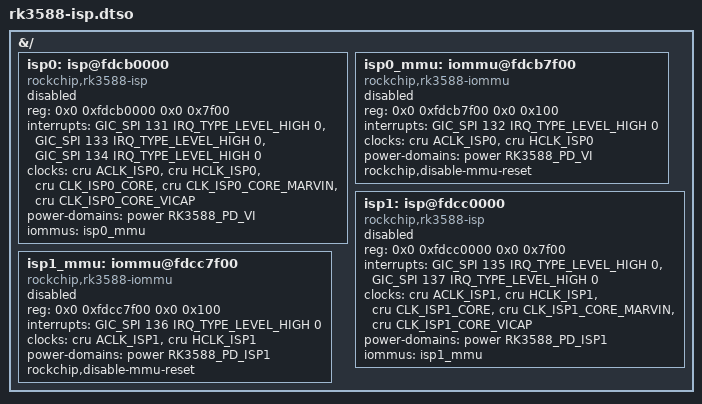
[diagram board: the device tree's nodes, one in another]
// SPDX-License-Identifier: (GPL-2.0+ OR MIT)
/*
 * RK3588 ISP nodes, generated by scripts/extract-oot-from-patches.sh from the
 * rk3588-base.dtsi hunk of patches/kernel/mainline/0002. Do not edit.
 *
 * Adds isp0/isp1 and their IOMMUs (disabled) for stock kernels whose DTBs
 * lack them. apply-overlays.sh applies this before any camera overlay.
 */

/dts-v1/;
/plugin/;

#include <dt-bindings/clock/rockchip,rk3588-cru.h>
#include <dt-bindings/interrupt-controller/arm-gic.h>
#include <dt-bindings/power/rk3588-power.h>

&{/} {
	isp0: isp@fdcb0000 {
		compatible = "rockchip,rk3588-isp";
		reg = <0x0 0xfdcb0000 0x0 0x7f00>;
		interrupts = <GIC_SPI 131 IRQ_TYPE_LEVEL_HIGH 0>,
			     <GIC_SPI 133 IRQ_TYPE_LEVEL_HIGH 0>,
			     <GIC_SPI 134 IRQ_TYPE_LEVEL_HIGH 0>;
		interrupt-names = "isp_irq", "mi_irq";
		clocks = <&cru ACLK_ISP0>, <&cru HCLK_ISP0>,
			 <&cru CLK_ISP0_CORE>, <&cru CLK_ISP0_CORE_MARVIN>,
			 <&cru CLK_ISP0_CORE_VICAP>;
		clock-names = "aclk", "hclk", "clk_core",
			      "clk_core_marvin", "clk_core_vicap";
		power-domains = <&power RK3588_PD_VI>;
		iommus = <&isp0_mmu>;
		status = "disabled";
	};

	isp0_mmu: iommu@fdcb7f00 {
		compatible = "rockchip,rk3588-iommu", "rockchip,rk3568-iommu";
		reg = <0x0 0xfdcb7f00 0x0 0x100>;
		interrupts = <GIC_SPI 132 IRQ_TYPE_LEVEL_HIGH 0>;
		clocks = <&cru ACLK_ISP0>, <&cru HCLK_ISP0>;
		clock-names = "aclk", "iface";
		power-domains = <&power RK3588_PD_VI>;
		#iommu-cells = <0>;
		rockchip,disable-mmu-reset;
		status = "disabled";
	};

	isp1: isp@fdcc0000 {
		compatible = "rockchip,rk3588-isp";
		reg = <0x0 0xfdcc0000 0x0 0x7f00>;
		interrupts = <GIC_SPI 135 IRQ_TYPE_LEVEL_HIGH 0>,
			     <GIC_SPI 137 IRQ_TYPE_LEVEL_HIGH 0>;
		interrupt-names = "isp_irq", "mi_irq";
		clocks = <&cru ACLK_ISP1>, <&cru HCLK_ISP1>,
			 <&cru CLK_ISP1_CORE>, <&cru CLK_ISP1_CORE_MARVIN>,
			 <&cru CLK_ISP1_CORE_VICAP>;
		clock-names = "aclk", "hclk", "clk_core",
			      "clk_core_marvin", "clk_core_vicap";
		power-domains = <&power RK3588_PD_ISP1>;
		iommus = <&isp1_mmu>;
		status = "disabled";
	};

	isp1_mmu: iommu@fdcc7f00 {
		compatible = "rockchip,rk3588-iommu", "rockchip,rk3568-iommu";
		reg = <0x0 0xfdcc7f00 0x0 0x100>;
		interrupts = <GIC_SPI 136 IRQ_TYPE_LEVEL_HIGH 0>;
		clocks = <&cru ACLK_ISP1>, <&cru HCLK_ISP1>;
		clock-names = "aclk", "iface";
		power-domains = <&power RK3588_PD_ISP1>;
		#iommu-cells = <0>;
		rockchip,disable-mmu-reset;
		status = "disabled";
	};
};
